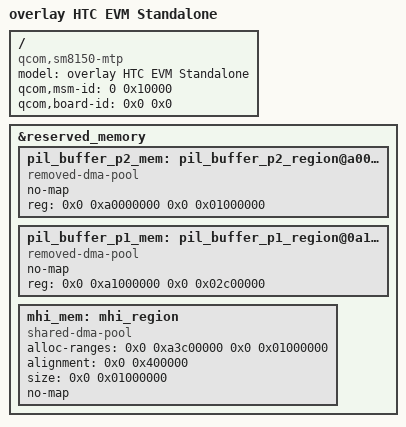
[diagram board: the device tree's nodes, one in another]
/* Copyright (c) 2018, The Linux Foundation. All rights reserved.
 *
 * This program is free software; you can redistribute it and/or modify
 * it under the terms of the GNU General Public License version 2 and
 * only version 2 as published by the Free Software Foundation.
 *
 * This program is distributed in the hope that it will be useful,
 * but WITHOUT ANY WARRANTY; without even the implied warranty of
 * MERCHANTABILITY or FITNESS FOR A PARTICULAR PURPOSE.  See the
 * GNU General Public License for more details.
 */

/dts-v1/;
/plugin/;

#include <dt-bindings/clock/qcom,gcc-sm8150.h>
#include <dt-bindings/clock/qcom,camcc-sm8150.h>
#include <dt-bindings/clock/qcom,rpmh.h>
#include <dt-bindings/interrupt-controller/arm-gic.h>

#include "../qcom/sm8150-mtp.dtsi"

#include "sm8150-htc-common.dtsi"
#include "sm8150-htc_evm.dtsi"
#include "sm8150-audio-evm.dtsi"    /* HTC_AUD */

/ {
	model = "overlay HTC EVM Standalone";
	compatible = "qcom,sm8150-mtp", "qcom,sm8150", "qcom,mtp";
	qcom,msm-id = <0 0x10000>;
	qcom,board-id = <0x0 0x0>;
};

&reserved_memory {
	pil_buffer_p2_mem: pil_buffer_p2_region@a0000000 {
		compatible = "removed-dma-pool";
		no-map;
		reg = <0x0 0xa0000000 0x0 0x01000000>;
	};


	pil_buffer_p1_mem: pil_buffer_p1_region@0a1000000 {
		compatible = "removed-dma-pool";
		no-map;
		reg = <0x0 0xa1000000 0x0 0x02c00000>;
	};

	mhi_mem: mhi_region {
		 compatible = "shared-dma-pool";
		 alloc-ranges = <0x0 0xa3c00000 0x0 0x01000000>;
		 alignment = <0x0 0x400000>;
		 size = <0x0 0x01000000>;
		 no-map;
	};
};
